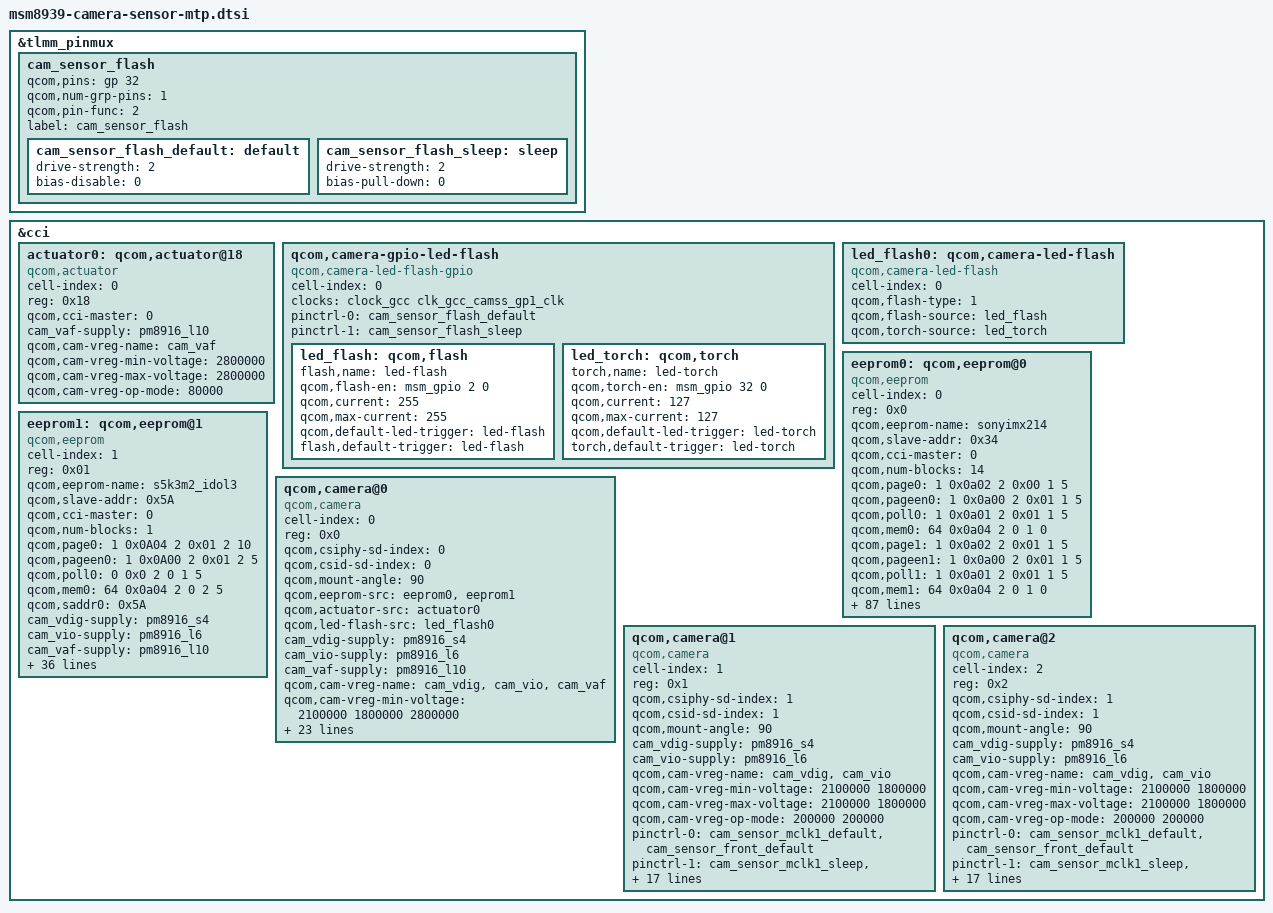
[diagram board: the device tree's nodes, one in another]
/*
 * Copyright (c) 2014, The Linux Foundation. All rights reserved.
 *
 * This program is free software; you can redistribute it and/or modify
 * it under the terms of the GNU General Public License version 2 and
 * only version 2 as published by the Free Software Foundation.
 *
 * This program is distributed in the hope that it will be useful,
 * but WITHOUT ANY WARRANTY; without even the implied warranty of
 * MERCHANTABILITY or FITNESS FOR A PARTICULAR PURPOSE.  See the
 * GNU General Public License for more details.
 */



/* [PLATFORM]-Add-BEGIN by TCTNB.YJ, for idol3 flash led driver. */
&tlmm_pinmux {
	 cam_sensor_flash {
	         /* FLSH_RESET,FLASH_EN,FLASH_NOW */
	         qcom,pins = <&gp 32> ;
	         qcom,num-grp-pins = <1>;
	         qcom,pin-func = <2>;
	         label = "cam_sensor_flash";
	         /* active state */
	         cam_sensor_flash_default: default {
	                 drive-strength = <2>; /* 2 MA */
	                 bias-disable = <0>; /* No PULL */
	         };
	         /*suspended state */
	         cam_sensor_flash_sleep: sleep {
	                 drive-strength = <2>; /* 2 MA */
	                 bias-pull-down = <0>; /* PULL DOWN */
	         };
	 };
};
/* [PLATFORM]-Mod-END by TCTNB.YJ */

&cci {

/* [PLATFORM]-Mod-BEGIN by TCTNB.YJ, add for rear camera on idol3  */
	actuator0: qcom,actuator@18 {
		cell-index = <0>;
		reg = <0x18>;
		compatible = "qcom,actuator";
		qcom,cci-master = <0>;
		cam_vaf-supply = <&pm8916_l10>;
		qcom,cam-vreg-name = "cam_vaf";
		qcom,cam-vreg-min-voltage = <2800000>;
		qcom,cam-vreg-max-voltage = <2800000>;
		qcom,cam-vreg-op-mode = <80000>;
	};
/* [PLATFORM]-Mod-END by TCTNB.YJ*/


/* [PLATFORM]-Add-BEGIN by TCTNB.YJ, for idol3 flash led driver. */
	qcom,camera-gpio-led-flash {
		cell-index = <0>;
		compatible = "qcom,camera-led-flash-gpio";
		status = "okay";
 	clocks = <&clock_gcc clk_gcc_camss_gp1_clk>;
		clock-names = "cam_sensor_flash";
		pinctrl-names = "default", "sleep";
		pinctrl-0 = <&cam_sensor_flash_default>;
		pinctrl-1 = <&cam_sensor_flash_sleep>;
		led_flash: qcom,flash {
			flash,name = "led-flash";
			qcom,flash-en = <&msm_gpio 2 0>;
			qcom,current = <255>;
			qcom,max-current = <255>;
            		qcom,default-led-trigger = "led-flash";
			flash,default-trigger = "led-flash";
		};
		led_torch: qcom,torch {
			torch,name = "led-torch";
			qcom,torch-en = <&msm_gpio 32 0>;
			qcom,current = <127>;
			qcom,max-current = <127>;
            		qcom,default-led-trigger = "led-torch";
			torch,default-trigger = "led-torch";
		};
	};

	led_flash0: qcom,camera-led-flash {
		cell-index = <0>;
		compatible = "qcom,camera-led-flash";
		qcom,flash-type = <1>;
		qcom,flash-source = <&led_flash>;
		qcom,torch-source = <&led_torch>;
	};

/*
	flashled,flash_driver {
		cell-index = <0>;
		compatible = "sgm3785";
		status = "okay";
              clocks = <&clock_gcc clk_gcc_camss_gp1_clk>;
              clock-names = "flash_pwm_clk";
		leds,flash-en = <&msm_gpio 2 0>;
		leds,torch-en = <&msm_gpio 32 0>;
              pinctrl-names = "default", "sleep";
              pinctrl-0 = <&cam_sensor_flash_default>;
              pinctrl-1 = <&cam_sensor_flash_sleep>;

		led_flash: qcom,flash {
			linux,name = "led-flash";
			qcom,current = <255>;
			qcom,max-current = <255>;
			linux,default-trigger = "flash-trigger";
		};

		led_torch: qcom,torch {
			linux,name = "led-torch";
			qcom,current = <127>;
			qcom,max-current = <127>;
			linux,default-trigger = "torch-trigger";
		};
	};

	led_flash0: qcom,camera-led-flash {
		cell-index = <0>;
		compatible = "qcom,camera-led-flash";
		qcom,flash-type = <1>;
		qcom,flash-source = <&led_flash>;
		qcom,torch-source = <&led_torch>;
	};
*/

/*
	led_flash0: qcom,led-flash@66 {
		cell-index = <0>;
		reg = <0x66>;
		qcom,slave-id = <0x66 0x00 0x0011>;
		compatible = "qcom,led-flash1";
		label = "bd7710";
		qcom,flash-type = <1>;
		qcom,gpio-no-mux = <0>;
		qcom,enable_pinctrl;
		pinctrl-names = "cam_flash_default", "cam_flash_suspend";
		pinctrl-0 = <&cam_sensor_flash_default>;
		pinctrl-1 = <&cam_sensor_flash_sleep>;
		gpios = <&msm_gpio 36 0>,
			<&msm_gpio 32 0>,
			<&msm_gpio 31 0>;
		qcom,gpio-flash-reset = <0>;
		qcom,gpio-flash-en = <1>;
		qcom,gpio-flash-now = <2>;
		qcom,gpio-req-tbl-num = <0 1 2>;
		qcom,gpio-req-tbl-flags = <0 0 0>;
		qcom,gpio-req-tbl-label = "FLASH_RST",
			"FLASH_EN",
			"FLASH_NOW";
		qcom,cci-master = <0>;
	};

	led_flash1: qcom,led-flash@60 {
		cell-index = <1>;
		reg = <0x60>;
		qcom,slave-id = <0x60 0x00 0x0011>;
		compatible = "qcom,led-flash";
		label = "adp1660";
		qcom,flash-type = <1>;
		qcom,gpio-no-mux = <0>;
		qcom,enable_pinctrl;
		pinctrl-names = "cam_flash_default", "cam_flash_suspend";
		pinctrl-0 = <&cam_sensor_flash_default>;
		pinctrl-1 = <&cam_sensor_flash_sleep>;
		gpios = <&msm_gpio 36 0>,
				<&msm_gpio 32 0>,
				<&msm_gpio 31 0>;
		qcom,gpio-flash-reset = <0>;
		qcom,gpio-flash-en = <1>;
		qcom,gpio-flash-now = <2>;
		qcom,gpio-req-tbl-num = <0 1 2>;
		qcom,gpio-req-tbl-flags = <0 0 0>;
		qcom,gpio-req-tbl-label = "FLASH_RST",
				"FLASH_EN",
				"FLASH_NOW";
		qcom,cci-master = <0>;
	};
*/
/* [PLATFORM]-Mod-END by TCTNB.YJ */

/* [PLATFORM]-Mod-BEGIN by TCTNB.YJ, add for rear camera on idol3  */

/*
	qcom,camera@78 {
		compatible = "ovti,ov5645";
		reg = <0x78 0x0>;
		qcom,slave-id = <0x78 0x300a 0x5645>;
		qcom,csiphy-sd-index = <1>;
		qcom,csid-sd-index = <1>;
		qcom,mount-angle = <90>;
		qcom,sensor-name = "ov5645";
		cam_vdig-supply = <&pm8916_s4>;
		cam_vana-supply = <&pm8916_l17>;
		cam_vio-supply = <&pm8916_l6>;
		qcom,cam-vreg-name = "cam_vdig", "cam_vio", "cam_vana";
		qcom,cam-vreg-min-voltage = <2100000 0 2850000>;
		qcom,cam-vreg-max-voltage = <2100000 0 2850000>;
		qcom,cam-vreg-op-mode = <200000 0 80000>;
		pinctrl-names = "cam_default", "cam_suspend";
		pinctrl-0 = <&cam_sensor_mclk1_default
				&cam_sensor_front_default>;
		pinctrl-1 = <&cam_sensor_mclk1_sleep &cam_sensor_front_sleep>;
		gpios = <&msm_gpio 27 0>,
			<&msm_gpio 28 0>,
			<&msm_gpio 33 0>;
		qcom,gpio-reset = <1>;
		qcom,gpio-standby = <2>;
		qcom,gpio-req-tbl-num = <0 1 2>;
		qcom,gpio-req-tbl-flags = <1 0 0>;
		qcom,gpio-req-tbl-label = "CAMIF_MCLK",
					"CAM_RESET",
					"CAM_STANDBY";
		qcom,gpio-set-tbl-num = <1 1>;
		qcom,gpio-set-tbl-flags = <0 2>;
		qcom,gpio-set-tbl-delay = <1000 4000>;
		qcom,csi-lane-assign = <0x4320>;
		qcom,csi-lane-mask = <0x3>;
		qcom,sensor-position = <1>;
		qcom,sensor-mode = <0>;
		qcom,cci-master = <0>;
		clocks = <&clock_gcc clk_mclk1_clk_src>,
				<&clock_gcc clk_gcc_camss_mclk1_clk>;
		clock-names = "cam_src_clk", "cam_clk";
	};
*/

	eeprom0: qcom,eeprom@0 {
		cell-index = <0>;
		reg = <0x0>;
		qcom,eeprom-name = "sonyimx214";
		compatible = "qcom,eeprom";
		qcom,slave-addr = <0x34>;
		qcom,cci-master = <0>;
		qcom,num-blocks = <14>;
		qcom,page0 = <1 0x0a02 2 0x00 1 5>;
		qcom,pageen0 = <1 0x0a00 2 0x01 1 5>;
		qcom,poll0 = <1 0x0a01 2 0x01 1 5>;
		qcom,mem0 = <64 0x0a04 2 0 1 0>;

		qcom,page1 = <1 0x0a02 2 0x01 1 5>;
		qcom,pageen1 = <1 0x0a00 2 0x01 1 5>;
		qcom,poll1 = <1 0x0a01 2 0x01 1 5>;
		qcom,mem1 = <64 0x0a04 2 0 1 0>;

		qcom,page2 = <1 0x0a02 2 0x02 1 5>;
		qcom,pageen2 = <1 0x0a00 2 0x01 1 5>;
		qcom,poll2 = <1 0x0a01 2 0x01 1 5>;
		qcom,mem2 = <64 0x0a04 2 0 1 0>;

		qcom,page3 = <1 0x0a02 2 0x03 1 5>;
		qcom,pageen3 = <1 0x0a00 2 0x01 1 5>;
		qcom,poll3 = <1 0x0a01 2 0x01 1 5>;
		qcom,mem3 = <64 0x0a04 2 0 1 0>;

		qcom,page4 = <1 0x0a02 2 0x04 1 5>;
		qcom,pageen4 = <1 0x0a00 2 0x01 1 5>;
		qcom,poll4 = <1 0x0a01 2 0x01 1 5>;
		qcom,mem4 = <64 0x0a04 2 0 1 0>;

		qcom,page5 = <1 0x0a02 2 0x05 1 5>;
		qcom,pageen5 = <1 0x0a00 2 0x01 1 5>;
		qcom,poll5 = <1 0x0a01 2 0x01 1 5>;
		qcom,mem5 = <64 0x0a04 2 0 1 0>;

		qcom,page6 = <1 0x0a02 2 0x06 1 5>;
		qcom,pageen6 = <1 0x0a00 2 0x01 1 5>;
		qcom,poll6 = <1 0x0a01 2 0x01 1 5>;
		qcom,mem6 = <64 0x0a04 2 0 1 0>;

		qcom,page7 = <1 0x0a02 2 0x07 1 5>;
		qcom,pageen7 = <1 0x0a00 2 0x01 1 5>;
		qcom,poll7 = <1 0x0a01 2 0x01 1 5>;
		qcom,mem7 = <64 0x0a04 2 0 1 0>;

		qcom,page8 = <1 0x0a02 2 0x08 1 5>;
		qcom,pageen8 = <1 0x0a00 2 0x01 1 5>;
		qcom,poll8 = <1 0x0a01 2 0x01 1 5>;
		qcom,mem8 = <64 0x0a04 2 0 1 0>;

		qcom,page9 = <1 0x0a02 2 0x09 1 5>;
		qcom,pageen9 = <1 0x0a00 2 0x01 1 5>;
		qcom,poll9 = <1 0x0a01 2 0x01 1 5>;
		qcom,mem9 = <64 0x0a04 2 0 1 0>;

		qcom,page10 = <1 0x0a02 2 0x0A 1 5>;
		qcom,pageen10 = <1 0x0a00 2 0x01 1 5>;
		qcom,poll10 = <1 0x0a01 2 0x01 1 5>;
		qcom,mem10 = <64 0x0a04 2 0 1 0>;

		qcom,page11 = <1 0x0a02 2 0x0B 1 5>;
		qcom,pageen11 = <1 0x0a00 2 0x01 1 5>;
		qcom,poll11 = <1 0x0a01 2 0x01 1 5>;
		qcom,mem11 = <64 0x0a04 2 0 1 0>;

		qcom,page12 = <1 0x0a02 2 0x0C 1 5>;
		qcom,pageen12 = <1 0x0a00 2 0x01 1 5>;
		qcom,poll12 = <1 0x0a01 2 0x01 1 5>;
		qcom,mem12 = <64 0x0a04 2 0 1 0>;

		qcom,page13 = <1 0x0a02 2 0x0D 1 5>;
		qcom,pageen13 = <1 0x0a00 2 0x01 1 5>;
		qcom,poll13 = <1 0x0a01 2 0x01 1 5>;
		qcom,mem13 = <64 0x0a04 2 0 1 0>;

		cam_vdig-supply = <&pm8916_s4>;
		cam_vio-supply = <&pm8916_l6>;
		cam_vaf-supply = <&pm8916_l10>;
		qcom,cam-vreg-name = "cam_vdig", "cam_vio", "cam_vaf";

		qcom,cam-vreg-min-voltage = <2100000 1800000 2800000>;
		qcom,cam-vreg-max-voltage = <2100000 1800000 2800000>;
		qcom,cam-vreg-op-mode = <200000 200000 200000>;
		qcom,gpio-no-mux = <0>;

		pinctrl-names = "cam_default", "cam_suspend";
		pinctrl-0 = <&cam_sensor_mclk0_default &cam_sensor_rear_default>;
		pinctrl-1 = <&cam_sensor_mclk0_sleep &cam_sensor_rear_sleep>;
		gpios = <&msm_gpio 26 0>,
			<&msm_gpio 35 0>,
			<&msm_gpio 94 0>,
			<&msm_gpio 17 0>,
			<&msm_gpio 16 0>;
		qcom,gpio-reset = <1>;
		qcom,gpio-standby = <2>;
              qcom,gpio-vana = <3>;
              qcom,gpio-vdig = <4>;
		qcom,gpio-req-tbl-num = <0 1 2 3 4>;
		qcom,gpio-req-tbl-flags = <1 0 0 0 0>;

		qcom,gpio-req-tbl-label = "CAMIF_MCLK0_E",
			"CAM_RESET0_E",
			"CAM_STANDBY0_E",
			"CAM_VANA_EN0_E",
			"CAM_VDIG_EN0_E";

                /*qcom,cam-power-seq-type = "sensor_gpio", "sensor_gpio", "sensor_gpio", "sensor_vreg", "sensor_vreg", "sensor_vreg",
                        "sensor_gpio", "sensor_gpio", "sensor_gpio", "sensor_gpio", "sensor_gpio", "sensor_clk";
                qcom,cam-power-seq-val = "sensor_gpio_standby", "sensor_gpio_reset", "sensor_gpio_vana", "cam_vio", "cam_vaf", "cam_vdig",
                        "sensor_gpio_vdig", "sensor_gpio_reset", "sensor_gpio_reset", "sensor_gpio_standby", "sensor_gpio_standby", "sensor_cam_mclk";
                qcom,cam-power-seq-cfg-val = <0 0 1 1 1 1 1 0 1 0 1 24000000>;
                qcom,cam-power-seq-delay = <1 1 1 1 1 2 1 1 1 1 1 5>;*/

                qcom,cam-power-seq-type = "sensor_gpio", "sensor_gpio", "sensor_gpio", "sensor_vreg", "sensor_vreg", "sensor_vreg",
                        "sensor_gpio", "sensor_gpio", "sensor_gpio", "sensor_clk";
                qcom,cam-power-seq-val = "sensor_gpio_standby", "sensor_gpio_reset", "sensor_gpio_vana", "cam_vio", "cam_vaf", "cam_vdig",
                        "sensor_gpio_vdig", "sensor_gpio_reset", "sensor_gpio_standby", "sensor_cam_mclk";
                qcom,cam-power-seq-cfg-val = <0 0 1 1 1 1 1 1 1 24000000>;
                qcom,cam-power-seq-delay = <2 2 1 1 1 2 1 1 1 5>;

		status = "ok";
		clocks = <&clock_gcc clk_mclk0_clk_src>,
				<&clock_gcc clk_gcc_camss_mclk0_clk>;
		clock-names = "cam_src_clk", "cam_clk";
	};

	eeprom1: qcom,eeprom@1 {
		 cell-index = <1>;
		 reg = <0x01>;
		 qcom,eeprom-name = "s5k3m2_idol3";
		 compatible = "qcom,eeprom";
		 qcom,slave-addr = <0x5A>;
		 qcom,cci-master = <0>;
		 qcom,num-blocks = <1>;

		 qcom,page0 = <1 0x0A04 2 0x01 2 10>;
        	 qcom,pageen0 = <1 0x0A00 2 0x01 2 5>; 
		 qcom,poll0 = <0 0x0 2 0 1 5>;
		 qcom,mem0 = <64 0x0a04 2 0 2 5>;
        	 qcom,saddr0 = <0x5A>;

		cam_vdig-supply = <&pm8916_s4>;
		cam_vio-supply = <&pm8916_l6>;
		cam_vaf-supply = <&pm8916_l10>;
		qcom,cam-vreg-name = "cam_vdig", "cam_vio", "cam_vaf";

		qcom,cam-vreg-min-voltage = <2100000 1800000 2800000>;
		qcom,cam-vreg-max-voltage = <2100000 1800000 2800000>;
		qcom,cam-vreg-op-mode = <200000 200000 200000>;
		qcom,gpio-no-mux = <0>;

		pinctrl-names = "cam_default", "cam_suspend";
		pinctrl-0 = <&cam_sensor_mclk0_default &cam_sensor_rear_default>;
		pinctrl-1 = <&cam_sensor_mclk0_sleep &cam_sensor_rear_sleep>;
		gpios = <&msm_gpio 26 0>,
			<&msm_gpio 35 0>,
			<&msm_gpio 94 0>,
			<&msm_gpio 17 0>,
			<&msm_gpio 16 0>;
		qcom,gpio-reset = <1>;
		qcom,gpio-standby = <2>;
              qcom,gpio-vana = <3>;
              qcom,gpio-vdig = <4>;
		qcom,gpio-req-tbl-num = <0 1 2 3 4>;
		qcom,gpio-req-tbl-flags = <1 0 0 0 0>;

		qcom,gpio-req-tbl-label = "CAMIF_MCLK0_E",
			"CAM_RESET0_E",
			"CAM_STANDBY0_E",
			"CAM_VANA_EN0_E",
			"CAM_VDIG_EN0_E";

                /*qcom,cam-power-seq-type = "sensor_gpio", "sensor_gpio", "sensor_gpio", "sensor_vreg", "sensor_vreg", "sensor_vreg",
                        "sensor_gpio", "sensor_gpio", "sensor_gpio", "sensor_gpio", "sensor_gpio", "sensor_clk";
                qcom,cam-power-seq-val = "sensor_gpio_standby", "sensor_gpio_reset", "sensor_gpio_vana", "cam_vio", "cam_vaf", "cam_vdig",
                        "sensor_gpio_vdig", "sensor_gpio_reset", "sensor_gpio_reset", "sensor_gpio_standby", "sensor_gpio_standby", "sensor_cam_mclk";
                qcom,cam-power-seq-cfg-val = <0 0 1 1 1 1 1 0 1 0 1 24000000>;
                qcom,cam-power-seq-delay = <1 1 1 1 1 2 1 1 1 1 1 5>;*/

                qcom,cam-power-seq-type = "sensor_gpio", "sensor_gpio", "sensor_gpio", "sensor_vreg", "sensor_vreg", "sensor_vreg",
                        "sensor_gpio", "sensor_gpio", "sensor_gpio", "sensor_clk";
                qcom,cam-power-seq-val = "sensor_gpio_standby", "sensor_gpio_reset", "sensor_gpio_vana", "cam_vio", "cam_vaf", "cam_vdig",
                        "sensor_gpio_vdig", "sensor_gpio_reset", "sensor_gpio_standby", "sensor_cam_mclk";
                qcom,cam-power-seq-cfg-val = <0 0 1 1 1 1 1 1 1 24000000>;
                qcom,cam-power-seq-delay = <2 2 1 1 1 2 1 1 1 5>;

		status = "ok";
		clocks = <&clock_gcc clk_mclk0_clk_src>,
				<&clock_gcc clk_gcc_camss_mclk0_clk>;
		clock-names = "cam_src_clk", "cam_clk";
	};

	qcom,camera@0 {
		cell-index = <0>;
		compatible = "qcom,camera";
		reg = <0x0>;
		qcom,csiphy-sd-index = <0>;
		qcom,csid-sd-index = <0>;
		qcom,mount-angle = <90>;
		qcom,eeprom-src = <&eeprom0 &eeprom1>;
		qcom,actuator-src = <&actuator0>;
		qcom,led-flash-src = <&led_flash0>;
		cam_vdig-supply = <&pm8916_s4>;
//		cam_vana-supply = <&pm8916_l17>;
		cam_vio-supply = <&pm8916_l6>;
		cam_vaf-supply = <&pm8916_l10>;
//		qcom,cam-vreg-name = "cam_vdig", "cam_vio", "cam_vana",
//							"cam_vaf";
		qcom,cam-vreg-name = "cam_vdig", "cam_vio", "cam_vaf";

		qcom,cam-vreg-min-voltage = <2100000 1800000 2800000>;
		qcom,cam-vreg-max-voltage = <2100000 1800000 2800000>;
		qcom,cam-vreg-op-mode = <200000 200000 200000>;
//		qcom,cam-vreg-op-mode = <200000 80000 100000>;
		pinctrl-names = "cam_default", "cam_suspend";
		pinctrl-0 = <&cam_sensor_mclk0_default
				&cam_sensor_rear_default>;
		pinctrl-1 = <&cam_sensor_mclk0_sleep &cam_sensor_rear_sleep>;
		gpios = <&msm_gpio 26 0>,
			<&msm_gpio 35 0>,
			<&msm_gpio 94 0>,
			<&msm_gpio 17 0>,
			<&msm_gpio 16 0>;
		qcom,gpio-reset = <1>;
		qcom,gpio-standby = <2>;
                qcom,gpio-vana = <3>;
                qcom,gpio-vdig = <4>;
		qcom,gpio-req-tbl-num = <0 1 2 3 4>;
		qcom,gpio-req-tbl-flags = <1 0 0 0 0>;
		qcom,gpio-req-tbl-label = "CAMIF_MCLK0",
			"CAM_RESET0",
			"CAM_STANDBY0",
			"CAM_VANA_EN0",
			"CAM_VDIG_EN0";
		qcom,sensor-position = <0>;
		qcom,sensor-mode = <0>;
		qcom,cci-master = <0>;
		status = "ok";
		clocks = <&clock_gcc clk_mclk0_clk_src>,
				<&clock_gcc clk_gcc_camss_mclk0_clk>;
		clock-names = "cam_src_clk", "cam_clk";
	};

	qcom,camera@1 {
		cell-index = <1>;
		compatible = "qcom,camera";
		reg = <0x1>;
		qcom,csiphy-sd-index = <1>;
		qcom,csid-sd-index = <1>;
		qcom,mount-angle = <90>;
		cam_vdig-supply = <&pm8916_s4>;
		cam_vio-supply = <&pm8916_l6>;
		qcom,cam-vreg-name = "cam_vdig", "cam_vio";

		qcom,cam-vreg-min-voltage = <2100000 1800000>;
		qcom,cam-vreg-max-voltage = <2100000 1800000>;
		qcom,cam-vreg-op-mode = <200000 200000>;
		pinctrl-names = "cam_default", "cam_suspend";
		pinctrl-0 = <&cam_sensor_mclk1_default &cam_sensor_front_default>;
		pinctrl-1 = <&cam_sensor_mclk1_sleep &cam_sensor_front_sleep>;
		gpios = <&msm_gpio 27 0>,
			<&msm_gpio 28 0>,
			<&msm_gpio 33 0>,
			<&msm_gpio 17 0>,
			<&msm_gpio 109 0>;
		qcom,gpio-reset = <1>;
		qcom,gpio-standby = <2>;
              qcom,gpio-vana = <3>;
              qcom,gpio-vdig = <4>;
		qcom,gpio-req-tbl-num = <0 1 2 3 4>;
		qcom,gpio-req-tbl-flags = <1 0 0 0 0>;
		qcom,gpio-req-tbl-label = "CAMIF_MCLK1",
			"CAM_RESET1",
			"CAM_STANDBY1",
			"CAM_VANA_EN1",
			"CAM_VDIG_EN1";
		qcom,sensor-position = <1>;
		qcom,sensor-mode = <0>;
		qcom,cci-master = <0>;
		status = "ok";
		clocks = <&clock_gcc clk_mclk1_clk_src>,
				<&clock_gcc clk_gcc_camss_mclk1_clk>;
		clock-names = "cam_src_clk", "cam_clk";
	};

	qcom,camera@2 {
		cell-index = <2>;
		compatible = "qcom,camera";
		reg = <0x2>;
		qcom,csiphy-sd-index = <1>;
		qcom,csid-sd-index = <1>;
		qcom,mount-angle = <90>;
		cam_vdig-supply = <&pm8916_s4>;
		cam_vio-supply = <&pm8916_l6>;
		qcom,cam-vreg-name = "cam_vdig", "cam_vio";

		qcom,cam-vreg-min-voltage = <2100000 1800000>;
		qcom,cam-vreg-max-voltage = <2100000 1800000>;
		qcom,cam-vreg-op-mode = <200000 200000>;
		pinctrl-names = "cam_default", "cam_suspend";
		pinctrl-0 = <&cam_sensor_mclk1_default &cam_sensor_front_default>;
		pinctrl-1 = <&cam_sensor_mclk1_sleep &cam_sensor_front_sleep>;
		gpios = <&msm_gpio 27 0>,
			<&msm_gpio 28 0>,
			<&msm_gpio 33 0>,
			<&msm_gpio 17 0>,
			<&msm_gpio 109 0>;
		qcom,gpio-reset = <1>;
		qcom,gpio-standby = <2>;
              qcom,gpio-vana = <3>;
              qcom,gpio-vdig = <4>;
		qcom,gpio-req-tbl-num = <0 1 2 3 4>;
		qcom,gpio-req-tbl-flags = <1 0 0 0 0>;
		qcom,gpio-req-tbl-label = "CAMIF_MCLK1",
			"CAM_RESET1",
			"CAM_STANDBY1",
			"CAM_VANA_EN1",
			"CAM_VDIG_EN1";
		qcom,sensor-position = <1>;
		qcom,sensor-mode = <0>;
		qcom,cci-master = <0>;
		status = "ok";
		clocks = <&clock_gcc clk_mclk1_clk_src>,
				<&clock_gcc clk_gcc_camss_mclk1_clk>;
		clock-names = "cam_src_clk", "cam_clk";
	};
/* [PLATFORM]-Mod-END by TCTNB.YJ*/

};
